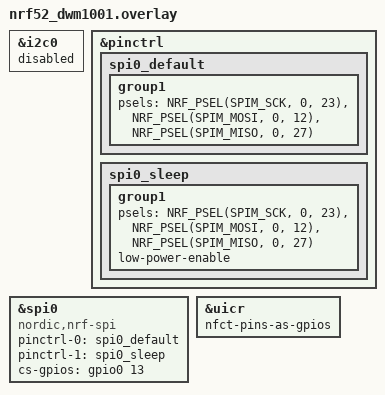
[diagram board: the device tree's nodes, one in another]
/*
 * Copyright (c) 2019 Callender-Consulting, LLC
 *
 * SPDX-License-Identifier: Apache-2.0
 */

&i2c0 {
	status = "disabled";
};

&pinctrl {
	spi0_default: spi0_default {
		group1 {
			psels = <NRF_PSEL(SPIM_SCK,  0, 23)>,
				    <NRF_PSEL(SPIM_MOSI, 0, 12)>,
				    <NRF_PSEL(SPIM_MISO, 0, 27)>;
		};
	};

	spi0_sleep: spi0_sleep {
		group1 {
			psels = <NRF_PSEL(SPIM_SCK,  0, 23)>,
				    <NRF_PSEL(SPIM_MOSI, 0, 12)>,
				    <NRF_PSEL(SPIM_MISO, 0, 27)>;
			low-power-enable;
		};
	};
};

&spi0 {
	compatible = "nordic,nrf-spi";
	status = "okay";
	pinctrl-0 = <&spi0_default>;
	pinctrl-1 = <&spi0_sleep>;
	pinctrl-names = "default", "sleep";
    cs-gpios = <&gpio0 13 0>;
};

&uicr {
    nfct-pins-as-gpios;
};
